AUTOSAR XML (schema 4-0-3)
package /Svc_DataLog
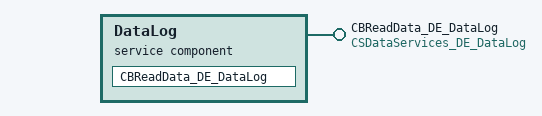
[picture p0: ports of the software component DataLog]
  service sw component type DataLog
    provide port CBReadData_DE_DataLog: server-com-spec{operation=ReadData, queue-length=1}, provided-interface=CSDataServices_DE_DataLog
    behavior SwcIB_DataLog
      operation invoked event OIE_CBReadData_DE_DataLog_CSDataServices_DE_DataLog_ReadData: start-on-event=CBReadData_DE_DataLog, operation=CBReadData_DE_DataLog.ReadData
      runnable CBReadData_DE_DataLog
